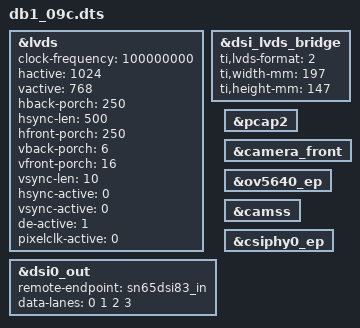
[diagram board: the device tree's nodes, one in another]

#include "apq8016-sbc.dts"

/*
 DB1 with 9.7" capacitive touch screen (ilitek_touch)
*/

/* Working frequency: 100MHz */
&lvds {
	clock-frequency = <100000000>;
	hactive = <1024>;
	vactive = <768>;
	hback-porch = <250>;
	hsync-len = <500>;
	hfront-porch = <250>;
	vback-porch = <6>;
	vfront-porch = <16>;
	vsync-len = <10>;
	hsync-active = <0>;
	vsync-active = <0>;
	de-active = <1>;
	pixelclk-active = <0>;
};


/* Working frequency 74.5MHz - Out of spec */
/*
&lvds {
        clock-frequency = <74592000>;
        hactive = <1024>;
        vactive = <768>;
        hback-porch = <240>;
        hsync-len = <160>;
        hfront-porch = <130>;
        vback-porch = <6>;
        vfront-porch = <16>;
        vsync-len = <10>;
        hsync-active = <0>;
        vsync-active = <0>;
        de-active = <1>;
        pixelclk-active = <0>;
};
*/


&dsi_lvds_bridge {
    /* MSB bits in 4th LVDS lane */
    ti,lvds-format = <2>;

	ti,width-mm = <197>;
	ti,height-mm = <147>;
};


&dsi0_out {
	remote-endpoint = <&sn65dsi83_in>;
	data-lanes = <0 1 2 3>;
};

/* ilitek touch screen */
&pcap2 {
    status = "okay";
};

/* camera support */
&camera_front
{
	status = "okay";
};

&ov5640_ep
{
	status = "okay";
};


&camss
{
	status = "okay";
};

&csiphy0_ep
{
	status = "okay";
};


